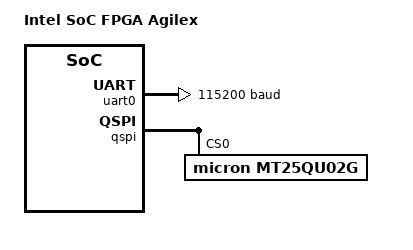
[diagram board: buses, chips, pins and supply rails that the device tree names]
/*
 * SPDX-License-Identifier: Apache-2.0
 *
 * Copyright (C) 2021, Intel Corporation
 *
 */

/dts-v1/;

#include <intel/intel_socfpga_agilex.dtsi>

/ {
	compatible = "intel,socfpga-agilex";
	model = "Intel SoC FPGA Agilex";
	#address-cells = <1>;
	#size-cells = <1>;

	chosen {
		zephyr,console = &uart0;
		zephyr,shell-uart = &uart0;
		zephyr,sram = &mem0;
	};
};

&uart0 {
	current-speed = <115200>;
	status = "okay";
};

&qspi {
	status = "okay";

	mt25qu02g@0 {
		compatible = "micron,mt25qu02g";
		reg = <0>;
		size = <DT_SIZE_M(256*8)>; /* in bits */
		status = "okay";
	};
};
